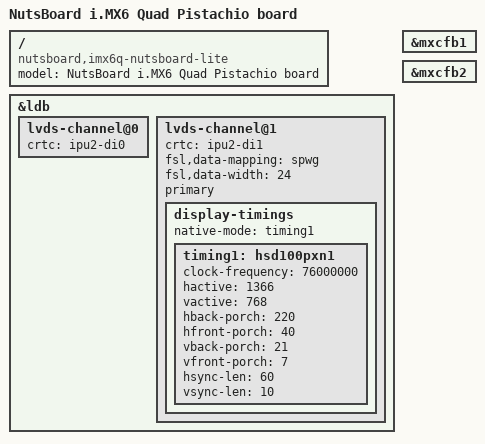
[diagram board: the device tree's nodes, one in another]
/*
 * Copyright 2017 NutsBoard.Org
 * Copyright 2012=2015 Freescale Semiconductor, Inc.
 * Copyright 2011 Linaro Ltd.
 *
 * The code contained herein is licensed under the GNU General Public
 * License. You may obtain a copy of the GNU General Public License
 * Version 2 or later at the following locations:
 *
 * http://www.opensource.org/licenses/gpl-license.html
 * http://www.gnu.org/copyleft/gpl.html
 */

/dts-v1/;

#include "imx6q.dtsi"
#include "imx6qdl-pistachio.dtsi"

/ {
	model = "NutsBoard i.MX6 Quad Pistachio board";
	compatible = "nutsboard,imx6q-nutsboard-lite", "fsl,imx6q";
};


&ldb {
	lvds-channel@0 {
		crtc = "ipu2-di0";
	};

	lvds-channel@1 {
		crtc = "ipu2-di1";
		fsl,data-mapping = "spwg";
		fsl,data-width = <24>;
		primary;
		status = "okay";

		display-timings {
			native-mode = <&timing1>;
			timing1: hsd100pxn1 {
				clock-frequency = <76000000>;
				hactive = <1366>;
				vactive = <768>;
				hback-porch = <220>;
				hfront-porch = <40>;
				vback-porch = <21>;
				vfront-porch = <7>;
				hsync-len = <60>;
				vsync-len = <10>;
			};
		};
	};
};

&mxcfb1 {
	status = "okay";
};

&mxcfb2 {
	status = "okay";
};
